# ESP32-H21 register map
Vendor: ESPRESSIF SYSTEMS (SHANGHAI) CO., LTD.; Series: ESP32 H-Series; File version: 1
CPU: RV32IMAC r0p0, little endian, no MPU, no FPU, 0 interrupt priority bits
Address unit: 32 bits
Registers are 32-bit, read-write, reset 0x0 unless marked. A register's access mark holds for its fields unless they carry their own. Offsets are from the block's base; [hi:lo] are bit positions.

## USB_DEVICE — Full-speed USB Serial/JTAG Controller
Base 0x6000F000
0x00 USB_SERIAL_JTAG_EP1 — FIFO access for the CDC-ACM data IN and OUT endpoints.
  [7:0] USB_SERIAL_JTAG_RDWR_BYTE — Write and read byte data to/from UART Tx/Rx FIFO through this field. When USB_SERIAL_JTAG_SERIAL_IN_EMPTY_INT is set, then user can write data (up to 64 bytes) into UART Tx FIFO. When USB_SERIAL_JTAG_SERIAL_OUT_RECV_PKT_INT is set, user can check USB_SERIAL_JTAG_OUT_EP1_WR_ADDR USB_SERIAL_JTAG_OUT_EP0_RD_ADDR to know how many data is received, then read data from UART Rx FIFO.
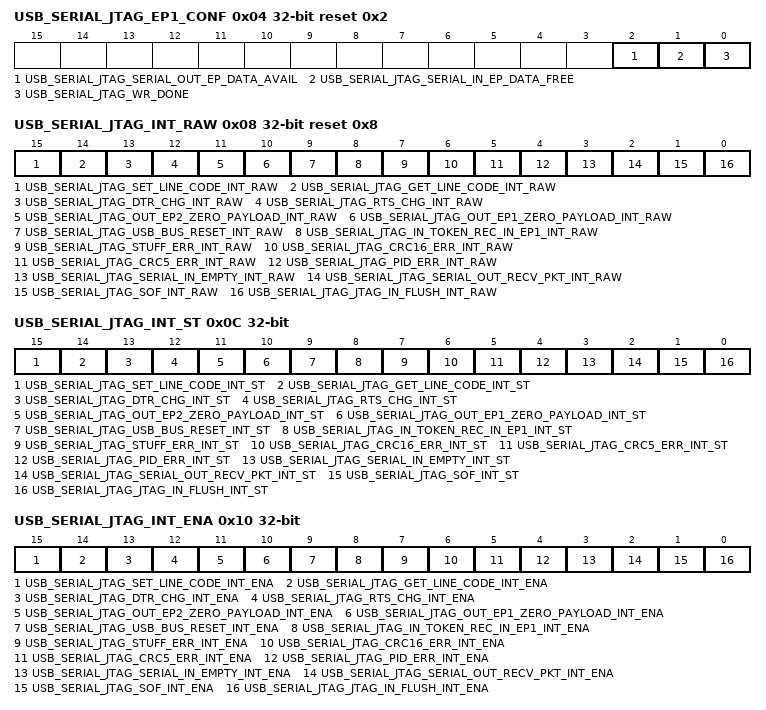
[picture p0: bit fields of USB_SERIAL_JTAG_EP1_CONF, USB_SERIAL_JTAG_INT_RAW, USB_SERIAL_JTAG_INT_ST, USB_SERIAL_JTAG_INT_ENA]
0x04 USB_SERIAL_JTAG_EP1_CONF access per field reset 0x2 — Configuration and control registers for the CDC-ACM FIFOs.
  [2] USB_SERIAL_JTAG_SERIAL_OUT_EP_DATA_AVAIL ro — 1'b1: Indicate there is data in UART Rx FIFO.
  [1] USB_SERIAL_JTAG_SERIAL_IN_EP_DATA_FREE ro — 1'b1: Indicate UART Tx FIFO is not full and can write data into in. After writing USB_SERIAL_JTAG_WR_DONE, this bit would be 0 until data in UART Tx FIFO is read by USB Host.
  [0] USB_SERIAL_JTAG_WR_DONE wo — Set this bit to indicate writing byte data to UART Tx FIFO is done.
0x08 USB_SERIAL_JTAG_INT_RAW reset 0x8 — Interrupt raw status register.
  [15] USB_SERIAL_JTAG_SET_LINE_CODE_INT_RAW — The raw interrupt bit turns to high level when level of SET LINE CODING request is received.
  [14] USB_SERIAL_JTAG_GET_LINE_CODE_INT_RAW — The raw interrupt bit turns to high level when level of GET LINE CODING request is received.
  [13] USB_SERIAL_JTAG_DTR_CHG_INT_RAW — The raw interrupt bit turns to high level when level of DTR from usb serial channel is changed.
  [12] USB_SERIAL_JTAG_RTS_CHG_INT_RAW — The raw interrupt bit turns to high level when level of RTS from usb serial channel is changed.
  [11] USB_SERIAL_JTAG_OUT_EP2_ZERO_PAYLOAD_INT_RAW — The raw interrupt bit turns to high level when OUT endpoint 2 received packet with zero palyload.
  [10] USB_SERIAL_JTAG_OUT_EP1_ZERO_PAYLOAD_INT_RAW — The raw interrupt bit turns to high level when OUT endpoint 1 received packet with zero palyload.
  [9] USB_SERIAL_JTAG_USB_BUS_RESET_INT_RAW — The raw interrupt bit turns to high level when usb bus reset is detected.
  [8] USB_SERIAL_JTAG_IN_TOKEN_REC_IN_EP1_INT_RAW — The raw interrupt bit turns to high level when IN token for IN endpoint 1 is received.
  [7] USB_SERIAL_JTAG_STUFF_ERR_INT_RAW — The raw interrupt bit turns to high level when stuff error is detected.
  [6] USB_SERIAL_JTAG_CRC16_ERR_INT_RAW — The raw interrupt bit turns to high level when CRC16 error is detected.
  [5] USB_SERIAL_JTAG_CRC5_ERR_INT_RAW — The raw interrupt bit turns to high level when CRC5 error is detected.
  [4] USB_SERIAL_JTAG_PID_ERR_INT_RAW — The raw interrupt bit turns to high level when pid error is detected.
  [3] USB_SERIAL_JTAG_SERIAL_IN_EMPTY_INT_RAW — The raw interrupt bit turns to high level when Serial Port IN Endpoint is empty.
  [2] USB_SERIAL_JTAG_SERIAL_OUT_RECV_PKT_INT_RAW — The raw interrupt bit turns to high level when Serial Port OUT Endpoint received one packet.
  [1] USB_SERIAL_JTAG_SOF_INT_RAW — The raw interrupt bit turns to high level when SOF frame is received.
  [0] USB_SERIAL_JTAG_JTAG_IN_FLUSH_INT_RAW — The raw interrupt bit turns to high level when flush cmd is received for IN endpoint 2 of JTAG.
0x0C USB_SERIAL_JTAG_INT_ST ro — Interrupt status register.
  [15] USB_SERIAL_JTAG_SET_LINE_CODE_INT_ST — The raw interrupt status bit for the USB_SERIAL_JTAG_SET_LINE_CODE_INT interrupt.
  [14] USB_SERIAL_JTAG_GET_LINE_CODE_INT_ST — The raw interrupt status bit for the USB_SERIAL_JTAG_GET_LINE_CODE_INT interrupt.
  [13] USB_SERIAL_JTAG_DTR_CHG_INT_ST — The raw interrupt status bit for the USB_SERIAL_JTAG_DTR_CHG_INT interrupt.
  [12] USB_SERIAL_JTAG_RTS_CHG_INT_ST — The raw interrupt status bit for the USB_SERIAL_JTAG_RTS_CHG_INT interrupt.
  [11] USB_SERIAL_JTAG_OUT_EP2_ZERO_PAYLOAD_INT_ST — The raw interrupt status bit for the USB_SERIAL_JTAG_OUT_EP2_ZERO_PAYLOAD_INT interrupt.
  [10] USB_SERIAL_JTAG_OUT_EP1_ZERO_PAYLOAD_INT_ST — The raw interrupt status bit for the USB_SERIAL_JTAG_OUT_EP1_ZERO_PAYLOAD_INT interrupt.
  [9] USB_SERIAL_JTAG_USB_BUS_RESET_INT_ST — The raw interrupt status bit for the USB_SERIAL_JTAG_USB_BUS_RESET_INT interrupt.
  [8] USB_SERIAL_JTAG_IN_TOKEN_REC_IN_EP1_INT_ST — The raw interrupt status bit for the USB_SERIAL_JTAG_IN_TOKEN_REC_IN_EP1_INT interrupt.
  [7] USB_SERIAL_JTAG_STUFF_ERR_INT_ST — The raw interrupt status bit for the USB_SERIAL_JTAG_STUFF_ERR_INT interrupt.
  [6] USB_SERIAL_JTAG_CRC16_ERR_INT_ST — The raw interrupt status bit for the USB_SERIAL_JTAG_CRC16_ERR_INT interrupt.
  [5] USB_SERIAL_JTAG_CRC5_ERR_INT_ST — The raw interrupt status bit for the USB_SERIAL_JTAG_CRC5_ERR_INT interrupt.
  [4] USB_SERIAL_JTAG_PID_ERR_INT_ST — The raw interrupt status bit for the USB_SERIAL_JTAG_PID_ERR_INT interrupt.
  [3] USB_SERIAL_JTAG_SERIAL_IN_EMPTY_INT_ST — The raw interrupt status bit for the USB_SERIAL_JTAG_SERIAL_IN_EMPTY_INT interrupt.
  [2] USB_SERIAL_JTAG_SERIAL_OUT_RECV_PKT_INT_ST — The raw interrupt status bit for the USB_SERIAL_JTAG_SERIAL_OUT_RECV_PKT_INT interrupt.
  [1] USB_SERIAL_JTAG_SOF_INT_ST — The raw interrupt status bit for the USB_SERIAL_JTAG_SOF_INT interrupt.
  [0] USB_SERIAL_JTAG_JTAG_IN_FLUSH_INT_ST — The raw interrupt status bit for the USB_SERIAL_JTAG_JTAG_IN_FLUSH_INT interrupt.
0x10 USB_SERIAL_JTAG_INT_ENA — Interrupt enable status register.
  [15] USB_SERIAL_JTAG_SET_LINE_CODE_INT_ENA — The interrupt enable bit for the USB_SERIAL_JTAG_SET_LINE_CODE_INT interrupt.
  [14] USB_SERIAL_JTAG_GET_LINE_CODE_INT_ENA — The interrupt enable bit for the USB_SERIAL_JTAG_GET_LINE_CODE_INT interrupt.
  [13] USB_SERIAL_JTAG_DTR_CHG_INT_ENA — The interrupt enable bit for the USB_SERIAL_JTAG_DTR_CHG_INT interrupt.
  [12] USB_SERIAL_JTAG_RTS_CHG_INT_ENA — The interrupt enable bit for the USB_SERIAL_JTAG_RTS_CHG_INT interrupt.
  [11] USB_SERIAL_JTAG_OUT_EP2_ZERO_PAYLOAD_INT_ENA — The interrupt enable bit for the USB_SERIAL_JTAG_OUT_EP2_ZERO_PAYLOAD_INT interrupt.
  [10] USB_SERIAL_JTAG_OUT_EP1_ZERO_PAYLOAD_INT_ENA — The interrupt enable bit for the USB_SERIAL_JTAG_OUT_EP1_ZERO_PAYLOAD_INT interrupt.
  [9] USB_SERIAL_JTAG_USB_BUS_RESET_INT_ENA — The interrupt enable bit for the USB_SERIAL_JTAG_USB_BUS_RESET_INT interrupt.
  [8] USB_SERIAL_JTAG_IN_TOKEN_REC_IN_EP1_INT_ENA — The interrupt enable bit for the USB_SERIAL_JTAG_IN_TOKEN_REC_IN_EP1_INT interrupt.
  [7] USB_SERIAL_JTAG_STUFF_ERR_INT_ENA — The interrupt enable bit for the USB_SERIAL_JTAG_STUFF_ERR_INT interrupt.
  [6] USB_SERIAL_JTAG_CRC16_ERR_INT_ENA — The interrupt enable bit for the USB_SERIAL_JTAG_CRC16_ERR_INT interrupt.
  [5] USB_SERIAL_JTAG_CRC5_ERR_INT_ENA — The interrupt enable bit for the USB_SERIAL_JTAG_CRC5_ERR_INT interrupt.
  [4] USB_SERIAL_JTAG_PID_ERR_INT_ENA — The interrupt enable bit for the USB_SERIAL_JTAG_PID_ERR_INT interrupt.
  [3] USB_SERIAL_JTAG_SERIAL_IN_EMPTY_INT_ENA — The interrupt enable bit for the USB_SERIAL_JTAG_SERIAL_IN_EMPTY_INT interrupt.
  [2] USB_SERIAL_JTAG_SERIAL_OUT_RECV_PKT_INT_ENA — The interrupt enable bit for the USB_SERIAL_JTAG_SERIAL_OUT_RECV_PKT_INT interrupt.
  [1] USB_SERIAL_JTAG_SOF_INT_ENA — The interrupt enable bit for the USB_SERIAL_JTAG_SOF_INT interrupt.
  [0] USB_SERIAL_JTAG_JTAG_IN_FLUSH_INT_ENA — The interrupt enable bit for the USB_SERIAL_JTAG_JTAG_IN_FLUSH_INT interrupt.
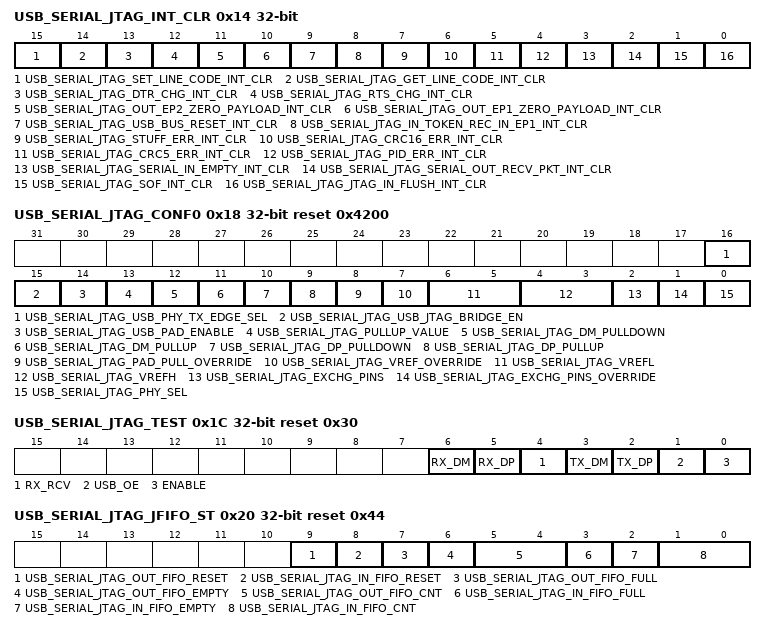
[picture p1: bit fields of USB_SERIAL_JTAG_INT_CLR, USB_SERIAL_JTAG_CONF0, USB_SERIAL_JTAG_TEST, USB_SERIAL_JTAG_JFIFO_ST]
0x14 USB_SERIAL_JTAG_INT_CLR wo — Interrupt clear status register.
  [15] USB_SERIAL_JTAG_SET_LINE_CODE_INT_CLR — Set this bit to clear the USB_SERIAL_JTAG_SET_LINE_CODE_INT interrupt.
  [14] USB_SERIAL_JTAG_GET_LINE_CODE_INT_CLR — Set this bit to clear the USB_SERIAL_JTAG_GET_LINE_CODE_INT interrupt.
  [13] USB_SERIAL_JTAG_DTR_CHG_INT_CLR — Set this bit to clear the USB_SERIAL_JTAG_DTR_CHG_INT interrupt.
  [12] USB_SERIAL_JTAG_RTS_CHG_INT_CLR — Set this bit to clear the USB_SERIAL_JTAG_RTS_CHG_INT interrupt.
  [11] USB_SERIAL_JTAG_OUT_EP2_ZERO_PAYLOAD_INT_CLR — Set this bit to clear the USB_SERIAL_JTAG_OUT_EP2_ZERO_PAYLOAD_INT interrupt.
  [10] USB_SERIAL_JTAG_OUT_EP1_ZERO_PAYLOAD_INT_CLR — Set this bit to clear the USB_SERIAL_JTAG_OUT_EP1_ZERO_PAYLOAD_INT interrupt.
  [9] USB_SERIAL_JTAG_USB_BUS_RESET_INT_CLR — Set this bit to clear the USB_SERIAL_JTAG_USB_BUS_RESET_INT interrupt.
  [8] USB_SERIAL_JTAG_IN_TOKEN_REC_IN_EP1_INT_CLR — Set this bit to clear the USB_SERIAL_JTAG_IN_TOKEN_IN_EP1_INT interrupt.
  [7] USB_SERIAL_JTAG_STUFF_ERR_INT_CLR — Set this bit to clear the USB_SERIAL_JTAG_STUFF_ERR_INT interrupt.
  [6] USB_SERIAL_JTAG_CRC16_ERR_INT_CLR — Set this bit to clear the USB_SERIAL_JTAG_CRC16_ERR_INT interrupt.
  [5] USB_SERIAL_JTAG_CRC5_ERR_INT_CLR — Set this bit to clear the USB_SERIAL_JTAG_CRC5_ERR_INT interrupt.
  [4] USB_SERIAL_JTAG_PID_ERR_INT_CLR — Set this bit to clear the USB_SERIAL_JTAG_PID_ERR_INT interrupt.
  [3] USB_SERIAL_JTAG_SERIAL_IN_EMPTY_INT_CLR — Set this bit to clear the USB_SERIAL_JTAG_SERIAL_IN_EMPTY_INT interrupt.
  [2] USB_SERIAL_JTAG_SERIAL_OUT_RECV_PKT_INT_CLR — Set this bit to clear the USB_SERIAL_JTAG_SERIAL_OUT_RECV_PKT_INT interrupt.
  [1] USB_SERIAL_JTAG_SOF_INT_CLR — Set this bit to clear the USB_SERIAL_JTAG_JTAG_SOF_INT interrupt.
  [0] USB_SERIAL_JTAG_JTAG_IN_FLUSH_INT_CLR — Set this bit to clear the USB_SERIAL_JTAG_JTAG_IN_FLUSH_INT interrupt.
0x18 USB_SERIAL_JTAG_CONF0 reset 0x4200 — PHY hardware configuration.
  [16] USB_SERIAL_JTAG_USB_PHY_TX_EDGE_SEL — Control at which clock edge the dp and dm are sent to USB PHY, 0: tx output at clock negative edge. 1: tx output at clock positive edge.
  [15] USB_SERIAL_JTAG_USB_JTAG_BRIDGE_EN — Set this bit usb_jtag, the connection between usb_jtag and internal JTAG is disconnected, and MTMS, MTDI, MTCK are output through GPIO Matrix, MTDO is input through GPIO Matrix.
  [14] USB_SERIAL_JTAG_USB_PAD_ENABLE — Enable USB pad function.
  [13] USB_SERIAL_JTAG_PULLUP_VALUE — Control pull up value.
  [12] USB_SERIAL_JTAG_DM_PULLDOWN — Control USB D- pull down.
  [11] USB_SERIAL_JTAG_DM_PULLUP — Control USB D- pull up.
  [10] USB_SERIAL_JTAG_DP_PULLDOWN — Control USB D+ pull down.
  [9] USB_SERIAL_JTAG_DP_PULLUP — Control USB D+ pull up.
  [8] USB_SERIAL_JTAG_PAD_PULL_OVERRIDE — Enable software control USB D+ D- pullup pulldown
  [7] USB_SERIAL_JTAG_VREF_OVERRIDE — Enable software control input threshold
  [6:5] USB_SERIAL_JTAG_VREFL — Control single-end input low threshold,0.8V to 1.04V, step 80mV
  [4:3] USB_SERIAL_JTAG_VREFH — Control single-end input high threshold,1.76V to 2V, step 80mV
  [2] USB_SERIAL_JTAG_EXCHG_PINS — USB D+ D- exchange
  [1] USB_SERIAL_JTAG_EXCHG_PINS_OVERRIDE — Enable software control USB D+ D- exchange
  [0] USB_SERIAL_JTAG_PHY_SEL — Select internal/external PHY
0x1C USB_SERIAL_JTAG_TEST access per field reset 0x30 — Registers used for debugging the PHY.
  [6] RX_DM ro — USB D- rx value in test
  [5] RX_DP ro — USB D+ rx value in test
  [4] RX_RCV ro — USB RCV value in test
  [3] TX_DM rw — USB D- tx value in test
  [2] TX_DP rw — USB D+ tx value in test
  [1] USB_OE rw — USB pad oen in test
  [0] ENABLE rw — Enable test of the USB pad
0x20 USB_SERIAL_JTAG_JFIFO_ST access per field reset 0x44 — JTAG FIFO status and control registers.
  [9] USB_SERIAL_JTAG_OUT_FIFO_RESET rw — Write 1 to reset JTAG out fifo.
  [8] USB_SERIAL_JTAG_IN_FIFO_RESET rw — Write 1 to reset JTAG in fifo.
  [7] USB_SERIAL_JTAG_OUT_FIFO_FULL ro — 1: JTAG out fifo is full.
  [6] USB_SERIAL_JTAG_OUT_FIFO_EMPTY ro — 1: JTAG out fifo is empty.
  [5:4] USB_SERIAL_JTAG_OUT_FIFO_CNT ro — JTAT out fifo counter.
  [3] USB_SERIAL_JTAG_IN_FIFO_FULL ro — 1: JTAG in fifo is full.
  [2] USB_SERIAL_JTAG_IN_FIFO_EMPTY ro — 1: JTAG in fifo is empty.
  [1:0] USB_SERIAL_JTAG_IN_FIFO_CNT ro — JTAT in fifo counter.
0x24 USB_SERIAL_JTAG_FRAM_NUM ro — Last received SOF frame index register.
  [10:0] USB_SERIAL_JTAG_SOF_FRAME_INDEX — Frame index of received SOF frame.
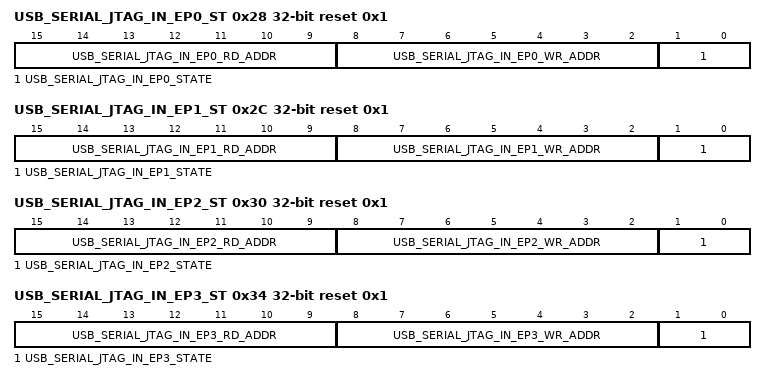
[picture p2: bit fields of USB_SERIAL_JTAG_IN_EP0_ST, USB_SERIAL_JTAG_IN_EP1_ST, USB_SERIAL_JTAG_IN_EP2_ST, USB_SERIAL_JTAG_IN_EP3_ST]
0x28 USB_SERIAL_JTAG_IN_EP0_ST ro reset 0x1 — Control IN endpoint status information.
  [15:9] USB_SERIAL_JTAG_IN_EP0_RD_ADDR — Read data address of IN endpoint 0.
  [8:2] USB_SERIAL_JTAG_IN_EP0_WR_ADDR — Write data address of IN endpoint 0.
  [1:0] USB_SERIAL_JTAG_IN_EP0_STATE — State of IN Endpoint 0.
0x2C USB_SERIAL_JTAG_IN_EP1_ST ro reset 0x1 — CDC-ACM IN endpoint status information.
  [15:9] USB_SERIAL_JTAG_IN_EP1_RD_ADDR — Read data address of IN endpoint 1.
  [8:2] USB_SERIAL_JTAG_IN_EP1_WR_ADDR — Write data address of IN endpoint 1.
  [1:0] USB_SERIAL_JTAG_IN_EP1_STATE — State of IN Endpoint 1.
0x30 USB_SERIAL_JTAG_IN_EP2_ST ro reset 0x1 — CDC-ACM interrupt IN endpoint status information.
  [15:9] USB_SERIAL_JTAG_IN_EP2_RD_ADDR — Read data address of IN endpoint 2.
  [8:2] USB_SERIAL_JTAG_IN_EP2_WR_ADDR — Write data address of IN endpoint 2.
  [1:0] USB_SERIAL_JTAG_IN_EP2_STATE — State of IN Endpoint 2.
0x34 USB_SERIAL_JTAG_IN_EP3_ST ro reset 0x1 — JTAG IN endpoint status information.
  [15:9] USB_SERIAL_JTAG_IN_EP3_RD_ADDR — Read data address of IN endpoint 3.
  [8:2] USB_SERIAL_JTAG_IN_EP3_WR_ADDR — Write data address of IN endpoint 3.
  [1:0] USB_SERIAL_JTAG_IN_EP3_STATE — State of IN Endpoint 3.
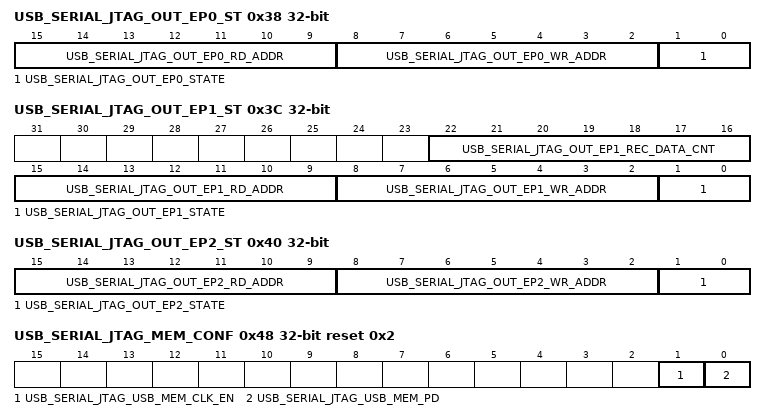
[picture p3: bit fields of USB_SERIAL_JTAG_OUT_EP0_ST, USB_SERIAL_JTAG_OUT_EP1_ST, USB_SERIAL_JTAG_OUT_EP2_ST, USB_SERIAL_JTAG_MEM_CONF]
0x38 USB_SERIAL_JTAG_OUT_EP0_ST ro — Control OUT endpoint status information.
  [15:9] USB_SERIAL_JTAG_OUT_EP0_RD_ADDR — Read data address of OUT endpoint 0.
  [8:2] USB_SERIAL_JTAG_OUT_EP0_WR_ADDR — Write data address of OUT endpoint 0. When USB_SERIAL_JTAG_SERIAL_OUT_RECV_PKT_INT is detected, there are USB_SERIAL_JTAG_OUT_EP0_WR_ADDR-2 bytes data in OUT EP0.
  [1:0] USB_SERIAL_JTAG_OUT_EP0_STATE — State of OUT Endpoint 0.
0x3C USB_SERIAL_JTAG_OUT_EP1_ST ro — CDC-ACM OUT endpoint status information.
  [22:16] USB_SERIAL_JTAG_OUT_EP1_REC_DATA_CNT — Data count in OUT endpoint 1 when one packet is received.
  [15:9] USB_SERIAL_JTAG_OUT_EP1_RD_ADDR — Read data address of OUT endpoint 1.
  [8:2] USB_SERIAL_JTAG_OUT_EP1_WR_ADDR — Write data address of OUT endpoint 1. When USB_SERIAL_JTAG_SERIAL_OUT_RECV_PKT_INT is detected, there are USB_SERIAL_JTAG_OUT_EP1_WR_ADDR-2 bytes data in OUT EP1.
  [1:0] USB_SERIAL_JTAG_OUT_EP1_STATE — State of OUT Endpoint 1.
0x40 USB_SERIAL_JTAG_OUT_EP2_ST ro — JTAG OUT endpoint status information.
  [15:9] USB_SERIAL_JTAG_OUT_EP2_RD_ADDR — Read data address of OUT endpoint 2.
  [8:2] USB_SERIAL_JTAG_OUT_EP2_WR_ADDR — Write data address of OUT endpoint 2. When USB_SERIAL_JTAG_SERIAL_OUT_RECV_PKT_INT is detected, there are USB_SERIAL_JTAG_OUT_EP2_WR_ADDR-2 bytes data in OUT EP2.
  [1:0] USB_SERIAL_JTAG_OUT_EP2_STATE — State of OUT Endpoint 2.
0x44 USB_SERIAL_JTAG_MISC_CONF — Clock enable control
  [0] USB_SERIAL_JTAG_CLK_EN — 1'h1: Force clock on for register. 1'h0: Support clock only when application writes registers.
0x48 USB_SERIAL_JTAG_MEM_CONF reset 0x2 — Memory power control
  [1] USB_SERIAL_JTAG_USB_MEM_CLK_EN — 1: Force clock on for usb memory.
  [0] USB_SERIAL_JTAG_USB_MEM_PD — 1: power down usb memory.
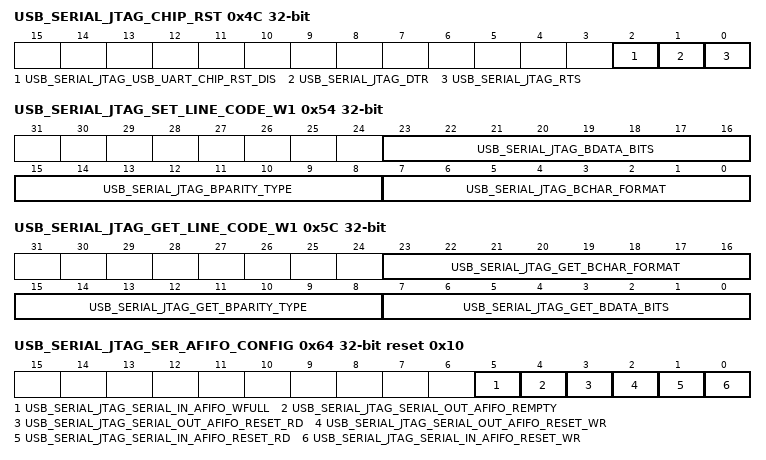
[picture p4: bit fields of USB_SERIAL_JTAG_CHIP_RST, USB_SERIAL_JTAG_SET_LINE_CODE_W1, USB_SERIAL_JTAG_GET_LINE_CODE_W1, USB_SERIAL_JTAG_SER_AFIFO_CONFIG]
0x4C USB_SERIAL_JTAG_CHIP_RST access per field — CDC-ACM chip reset control.
  [2] USB_SERIAL_JTAG_USB_UART_CHIP_RST_DIS rw — Set this bit to disable chip reset from usb serial channel to reset chip.
  [1] USB_SERIAL_JTAG_DTR ro — 1: Chip reset is detected from usb jtag channel. Software write 1 to clear it.
  [0] USB_SERIAL_JTAG_RTS ro — 1: Chip reset is detected from usb serial channel. Software write 1 to clear it.
0x50 USB_SERIAL_JTAG_SET_LINE_CODE_W0 ro — W0 of SET_LINE_CODING command.
  [31:0] USB_SERIAL_JTAG_DW_DTE_RATE — The value of dwDTERate set by host through SET_LINE_CODING command.
0x54 USB_SERIAL_JTAG_SET_LINE_CODE_W1 ro — W1 of SET_LINE_CODING command.
  [23:16] USB_SERIAL_JTAG_BDATA_BITS — The value of bDataBits set by host through SET_LINE_CODING command.
  [15:8] USB_SERIAL_JTAG_BPARITY_TYPE — The value of bParityTpye set by host through SET_LINE_CODING command.
  [7:0] USB_SERIAL_JTAG_BCHAR_FORMAT — The value of bCharFormat set by host through SET_LINE_CODING command.
0x58 USB_SERIAL_JTAG_GET_LINE_CODE_W0 — W0 of GET_LINE_CODING command.
  [31:0] USB_SERIAL_JTAG_GET_DW_DTE_RATE — The value of dwDTERate set by software which is requested by GET_LINE_CODING command.
0x5C USB_SERIAL_JTAG_GET_LINE_CODE_W1 — W1 of GET_LINE_CODING command.
  [23:16] USB_SERIAL_JTAG_GET_BCHAR_FORMAT — The value of bDataBits set by software which is requested by GET_LINE_CODING command.
  [15:8] USB_SERIAL_JTAG_GET_BPARITY_TYPE — The value of bParityTpye set by software which is requested by GET_LINE_CODING command.
  [7:0] USB_SERIAL_JTAG_GET_BDATA_BITS — The value of bCharFormat set by software which is requested by GET_LINE_CODING command.
0x60 USB_SERIAL_JTAG_CONFIG_UPDATE wo — Configuration registers' value update
  [0] USB_SERIAL_JTAG_CONFIG_UPDATE — Write 1 to this register would update the value of configure registers from APB clock domain to 48MHz clock domain.
0x64 USB_SERIAL_JTAG_SER_AFIFO_CONFIG access per field reset 0x10 — Serial AFIFO configure register
  [5] USB_SERIAL_JTAG_SERIAL_IN_AFIFO_WFULL ro — CDC_ACM OUT IN async FIFO empty signal in write clock domain.
  [4] USB_SERIAL_JTAG_SERIAL_OUT_AFIFO_REMPTY ro — CDC_ACM OUTOUT async FIFO empty signal in read clock domain.
  [3] USB_SERIAL_JTAG_SERIAL_OUT_AFIFO_RESET_RD rw — Write 1 to reset CDC_ACM OUT async FIFO read clock domain.
  [2] USB_SERIAL_JTAG_SERIAL_OUT_AFIFO_RESET_WR rw — Write 1 to reset CDC_ACM OUT async FIFO write clock domain.
  [1] USB_SERIAL_JTAG_SERIAL_IN_AFIFO_RESET_RD rw — Write 1 to reset CDC_ACM IN async FIFO read clock domain.
  [0] USB_SERIAL_JTAG_SERIAL_IN_AFIFO_RESET_WR rw — Write 1 to reset CDC_ACM IN async FIFO write clock domain.
0x68 USB_SERIAL_JTAG_BUS_RESET_ST ro reset 0x1 — USB Bus reset status register
  [0] USB_SERIAL_JTAG_USB_BUS_RESET_ST — USB bus reset status. 0: USB-Serial-JTAG is in usb bus reset status. 1: USB bus reset is released.
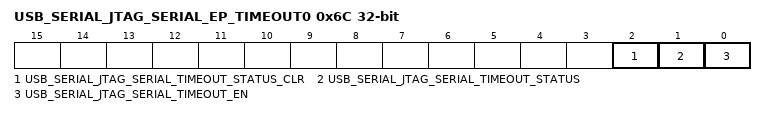
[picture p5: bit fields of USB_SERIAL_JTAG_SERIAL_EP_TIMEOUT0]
0x6C USB_SERIAL_JTAG_SERIAL_EP_TIMEOUT0 access per field — USB uart out endpoint timeout configuration.
  [2] USB_SERIAL_JTAG_SERIAL_TIMEOUT_STATUS_CLR wo — Write 1 to clear reg_serial_timeout_status.
  [1] USB_SERIAL_JTAG_SERIAL_TIMEOUT_STATUS rw — Serial out ep triggers a timeout event.
  [0] USB_SERIAL_JTAG_SERIAL_TIMEOUT_EN rw — USB serial out ep timeout enable. When a timeout event occurs, serial out ep buffer is automatically cleared and reg_serial_timeout_status is asserted.
0x70 USB_SERIAL_JTAG_SERIAL_EP_TIMEOUT1 reset 0x494100 — USB uart out endpoint timeout configuration.
  [31:0] USB_SERIAL_JTAG_SERIAL_TIMEOUT_MAX — USB serial out ep timeout max threshold value, indicates the maximum time that waiting for ESP to take away data in memory. This value is in steps of 20.83ns.
0x80 USB_SERIAL_JTAG_DATE reset 0x2407030 — Date register
  [31:0] USB_SERIAL_JTAG_DATE — register version.
